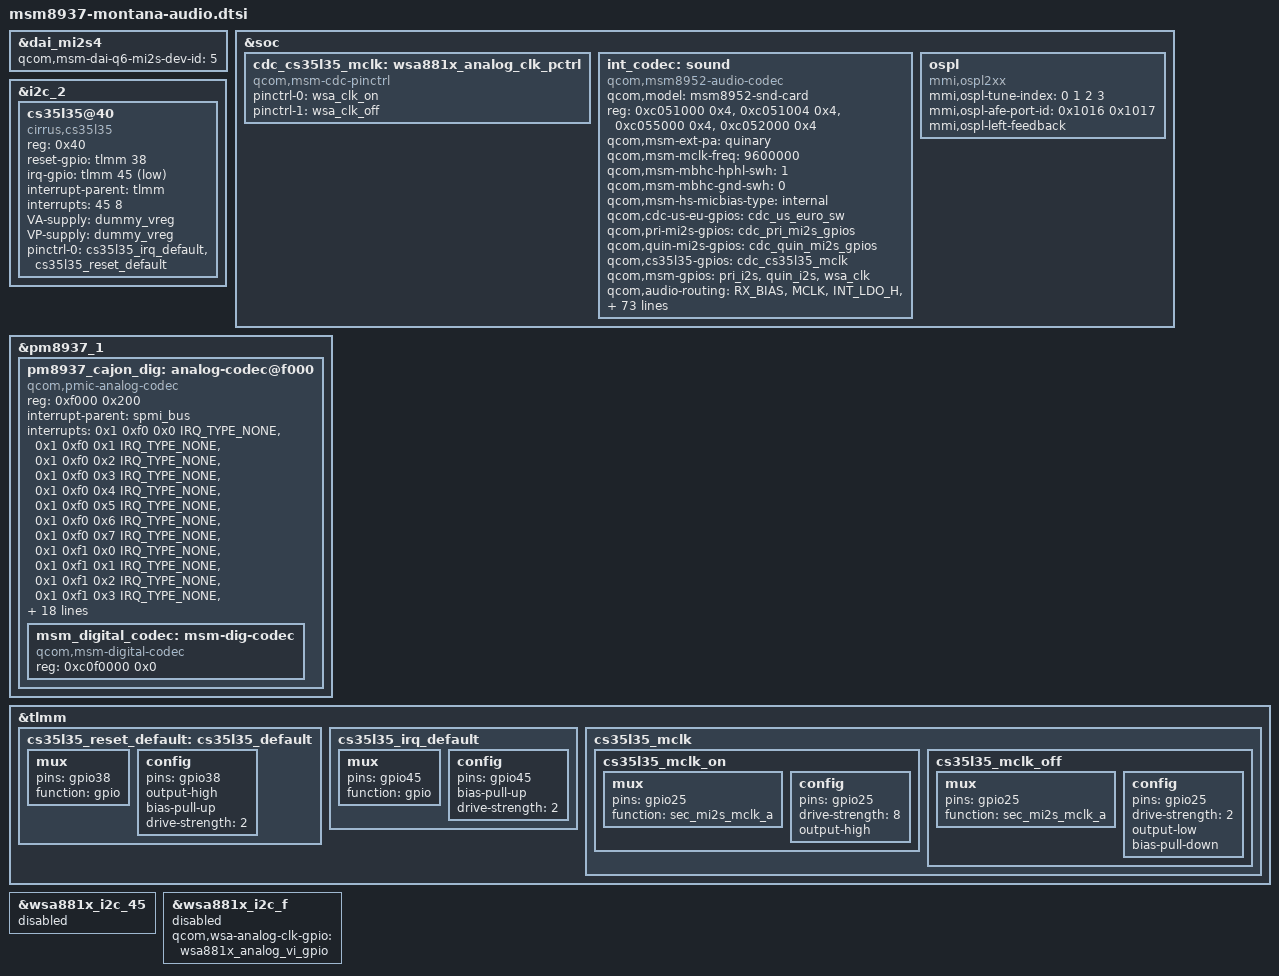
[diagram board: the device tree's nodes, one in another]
/*
 * Copyright (c) 2018, The Linux Foundation. All rights reserved.
 *
 * This program is free software; you can redistribute it and/or modify
 * it under the terms of the GNU General Public License version 2 and
 * only version 2 as published by the Free Software Foundation.
 *
 * This program is distributed in the hope that it will be useful,
 * but WITHOUT ANY WARRANTY; without even the implied warranty of
 * MERCHANTABILITY or FITNESS FOR A PARTICULAR PURPOSE.  See the
 * GNU General Public License for more details.
 */

&dai_mi2s4 {
	qcom,msm-dai-q6-mi2s-dev-id = <5>;
};

&soc {
	/delete-node/ wsa881x_analog_clk_pctrl;

	cdc_cs35l35_mclk: wsa881x_analog_clk_pctrl {
		compatible = "qcom,msm-cdc-pinctrl";
		pinctrl-names = "aud_active", "aud_sleep";
		pinctrl-0 = <&wsa_clk_on>;
		pinctrl-1 = <&wsa_clk_off>;
	};

	int_codec: sound {
		status = "okay";
		compatible = "qcom,msm8952-audio-codec";
		qcom,model = "msm8952-snd-card";

		reg = <0xc051000 0x4>,
			<0xc051004 0x4>,
			<0xc055000 0x4>,
			<0xc052000 0x4>;
		reg-names = "csr_gp_io_mux_mic_ctl",
			"csr_gp_io_mux_spkr_ctl",
			"csr_gp_io_lpaif_pri_pcm_pri_mode_muxsel",
			"csr_gp_io_mux_quin_ctl";

		qcom,msm-ext-pa = "quinary";
		qcom,msm-mclk-freq = <9600000>;
		qcom,msm-mbhc-hphl-swh = <1>;
		qcom,msm-mbhc-gnd-swh = <0>;
		qcom,msm-hs-micbias-type = "internal";

		qcom,cdc-us-eu-gpios = <&cdc_us_euro_sw>;
		qcom,pri-mi2s-gpios = <&cdc_pri_mi2s_gpios>;
		qcom,quin-mi2s-gpios = <&cdc_quin_mi2s_gpios>;
		qcom,cs35l35-gpios = <&cdc_cs35l35_mclk>;

		/delete-property/ qcom,cdc-us-euro-gpios;
		/delete-property/ qcom,msm-micbias1-ext-cap;
		/delete-property/ qcom,msm-micbias2-ext-cap;

		qcom,msm-gpios =
			"pri_i2s",
			"quin_i2s",
			"wsa_clk";

		qcom,audio-routing =
			"RX_BIAS", "MCLK",
			"INT_LDO_H", "MCLK",
			"MIC BIAS External", "Handset Mic",
			"MIC BIAS Internal2", "Headset Mic",
			"MIC BIAS External", "Secondary Mic",
			"AMIC1", "MIC BIAS External",
			"AMIC2", "MIC BIAS Internal2",
			"AMIC3", "MIC BIAS External";

		asoc-platform = <&pcm0>, <&pcm1>, <&pcm2>, <&voip>, <&voice>,
				<&loopback>, <&compress>, <&hostless>,
				<&afe>, <&lsm>, <&routing>, <&pcm_noirq>;
		asoc-platform-names = "msm-pcm-dsp.0", "msm-pcm-dsp.1",
				"msm-pcm-dsp.2", "msm-voip-dsp",
				"msm-pcm-voice", "msm-pcm-loopback",
				"msm-compress-dsp", "msm-pcm-hostless",
				"msm-pcm-afe", "msm-lsm-client",
				"msm-pcm-routing", "msm-pcm-dsp-noirq";
		asoc-cpu = <&dai_pri_auxpcm>,
			<&dai_mi2s0>, <&dai_mi2s1>,
			<&dai_mi2s2>, <&dai_mi2s3>,
			<&dai_mi2s4>, <&dai_mi2s6>,
			<&sb_0_rx>, <&sb_0_tx>, <&sb_1_rx>, <&sb_1_tx>,
			<&sb_3_rx>, <&sb_3_tx>, <&sb_4_rx>, <&sb_4_tx>,
			<&bt_sco_rx>, <&bt_sco_tx>,
			<&int_fm_rx>, <&int_fm_tx>,
			<&afe_pcm_rx>, <&afe_pcm_tx>,
			<&afe_proxy_rx>, <&afe_proxy_tx>,
			<&incall_record_rx>, <&incall_record_tx>,
			<&incall_music_rx>, <&incall_music_2_rx>;

		asoc-cpu-names = "msm-dai-q6-auxpcm.1",
				"msm-dai-q6-mi2s.0", "msm-dai-q6-mi2s.1",
				"msm-dai-q6-mi2s.2", "msm-dai-q6-mi2s.3",
				"msm-dai-q6-mi2s.4", "msm-dai-q6-mi2s.6",
				"msm-dai-q6-dev.16384", "msmdai-q6-dev.16385",
				"msm-dai-q6-dev.16386", "msm-dai-q6-dev.16387",
				"msm-dai-q6-dev.16390", "msm-dai-q6-dev.16391",
				"msm-dai-q6-dev.16392", "msm-dai-q6-dev.16393",
				"msm-dai-q6-dev.12288", "msm-dai-q6-dev.12289",
				"msm-dai-q6-dev.12292", "msm-dai-q6-dev.12293",
				"msm-dai-q6-dev.224", "msm-dai-q6-dev.225",
				"msm-dai-q6-dev.241", "msm-dai-q6-dev.240",
				"msm-dai-q6-dev.32771", "msm-dai-q6-dev.32772",
				"msm-dai-q6-dev.32773", "msm-dai-q6-dev.32770";

		asoc-codec = <&stub_codec>, <&pm8937_cajon_dig>, <&msm_digital_codec>;
		asoc-codec-names = "msm-stub-codec.1", "analog-codec", "msm-dig-codec";

		msm-vdd-wsa-switch-supply = <&pm8937_l5>;
		qcom,msm-vdd-wsa-switch-voltage = <1800000>;
		qcom,msm-vdd-wsa-switch-current = <10000>;

		qcom,pinctrl-names =
			"all_off",
			"pri_i2s_act",
			"quin_act",
			"quin_pri_i2s_act",
			"cs35l35_mclk_act",
			"cs35l35_mclk_pri_i2s_act",
			"cs35l35_mclk_quin_act",
			"cs35l35_mclk_quin_pri_i2s_act";
		pinctrl-names =
			"all_off",
			"pri_i2s_act",
			"quin_act",
			"quin_pri_i2s_act",
			"cs35l35_mclk_act",
			"cs35l35_mclk_pri_i2s_act",
			"cs35l35_mclk_quin_act",
			"cs35l35_mclk_quin_pri_i2s_act";
		pinctrl-0 = <&cdc_pdm_lines_sus &cdc_pdm_lines_2_sus
			&pri_tlmm_lines_sus &pri_tlmm_ws_sus &wsa_clk_off>;
		pinctrl-1 = <&cdc_pdm_lines_act &cdc_pdm_lines_2_act
			&pri_tlmm_lines_sus &pri_tlmm_ws_sus &wsa_clk_off>;
		pinctrl-2 = <&cdc_pdm_lines_sus &cdc_pdm_lines_2_sus
			&pri_tlmm_lines_act &pri_tlmm_ws_act &wsa_clk_off>;
		pinctrl-3 = <&cdc_pdm_lines_act &cdc_pdm_lines_2_act
			&pri_tlmm_lines_act &pri_tlmm_ws_act &wsa_clk_off>;
		pinctrl-4 = <&cdc_pdm_lines_sus &cdc_pdm_lines_2_sus
			&pri_tlmm_lines_sus &pri_tlmm_ws_sus &wsa_clk_on>;
		pinctrl-5 = <&cdc_pdm_lines_act &cdc_pdm_lines_2_act
			&pri_tlmm_lines_sus &pri_tlmm_ws_sus &wsa_clk_on>;
		pinctrl-6 = <&cdc_pdm_lines_sus &cdc_pdm_lines_2_sus
			&pri_tlmm_lines_act &pri_tlmm_ws_act &wsa_clk_on>;
		pinctrl-7 = <&cdc_pdm_lines_act &cdc_pdm_lines_2_act
			&pri_tlmm_lines_act &pri_tlmm_ws_act &wsa_clk_on>;

		/delete-property/ asoc-wsa-codec-names;
		/delete-property/ asoc-wsa-codec-prefixes;
		/delete-property/ qcom,hdmi-dba-codec-rx;
	};

	ospl {
		compatible = "mmi,ospl2xx";
		status = "ok";
		mmi,ospl-tune-index = <0 1 2 3>;
		mmi,ospl-afe-port-id = <0x1016 0x1017>;
		mmi,ospl-left-feedback;
	};
};

&i2c_2 {
	cs35l35@40 {
		compatible = "cirrus,cs35l35";
		reg = <0x40>;
		reset-gpio = <&tlmm 38 0>;
		irq-gpio = <&tlmm 45 1>;
		interrupt-parent = <&tlmm>;
		interrupts = <45 8>;

		VA-supply = <&dummy_vreg>;
		VP-supply = <&dummy_vreg>;
		pinctrl-names = "default";
		pinctrl-0 = <&cs35l35_irq_default &cs35l35_reset_default>;
	};
};

&pm8937_1 {
	pm8937_cajon_dig: analog-codec@f000 {
		compatible = "qcom,pmic-analog-codec";
		reg = <0xf000 0x200>;
		interrupt-parent = <&spmi_bus>;
		interrupts = <0x1 0xf0 0x0 IRQ_TYPE_NONE>,
			     <0x1 0xf0 0x1 IRQ_TYPE_NONE>,
			     <0x1 0xf0 0x2 IRQ_TYPE_NONE>,
			     <0x1 0xf0 0x3 IRQ_TYPE_NONE>,
			     <0x1 0xf0 0x4 IRQ_TYPE_NONE>,
			     <0x1 0xf0 0x5 IRQ_TYPE_NONE>,
			     <0x1 0xf0 0x6 IRQ_TYPE_NONE>,
			     <0x1 0xf0 0x7 IRQ_TYPE_NONE>,
			     <0x1 0xf1 0x0 IRQ_TYPE_NONE>,
			     <0x1 0xf1 0x1 IRQ_TYPE_NONE>,
			     <0x1 0xf1 0x2 IRQ_TYPE_NONE>,
			     <0x1 0xf1 0x3 IRQ_TYPE_NONE>,
			     <0x1 0xf1 0x4 IRQ_TYPE_NONE>,
			     <0x1 0xf1 0x5 IRQ_TYPE_NONE>;
		interrupt-names = "spk_cnp_int",
				  "spk_clip_int",
				  "spk_ocp_int",
				  "ins_rem_det1",
				  "but_rel_det",
				  "but_press_det",
				  "ins_rem_det",
				  "mbhc_int",
				  "ear_ocp_int",
				  "hphr_ocp_int",
				  "hphl_ocp_det",
				  "ear_cnp_int",
				  "hphr_cnp_int",
				  "hphl_cnp_int";

		cdc-vdda-cp-supply = <&pm8937_s4>;
		qcom,cdc-vdda-cp-voltage = <2050000 2050000>;
		qcom,cdc-vdda-cp-current = <210000>;

		cdc-vdd-io-supply = <&pm8937_l5>;
		qcom,cdc-vdd-io-voltage = <1800000 1800000>;
		qcom,cdc-vdd-io-current = <5000>;

		cdc-vdd-pa-supply = <&pm8937_s4>;
		qcom,cdc-vdd-pa-voltage = <2050000 2050000>;
		qcom,cdc-vdd-pa-current = <260000>;

		cdc-vdd-mic-bias-supply = <&pm8937_l13>;
		qcom,cdc-vdd-mic-bias-voltage = <3075000 3075000>;
		qcom,cdc-vdd-mic-bias-current = <5000>;

		qcom,cdc-mclk-clk-rate = <9600000>;

		qcom,cdc-static-supplies = "cdc-vdd-io",
						"cdc-vdd-pa",
						"cdc-vdda-cp";

		qcom,cdc-on-demand-supplies = "cdc-vdd-mic-bias";

		msm_digital_codec: msm-dig-codec {
			compatible = "qcom,msm-digital-codec";
			reg = <0xc0f0000 0x0>;
		};
	};
};

&tlmm {
	cs35l35_reset_default: cs35l35_default{
		mux {
			pins = "gpio38";
			function = "gpio";
		};

		config {
			pins = "gpio38";
			output-high;
			bias-pull-up;
			drive-strength = <2>;
		};
	};

	cs35l35_irq_default: cs35l35_irq_default {
		mux {
			pins = "gpio45";
			function = "gpio";
		};

		config {
			pins = "gpio45";
			bias-pull-up;
			drive-strength = <2>;
		};
	};

	cs35l35_mclk {
		cs35l35_mclk_on: cs35l35_mclk_on {
			mux {
				pins = "gpio25";
				function = "sec_mi2s_mclk_a";
			};

			config {
				pins = "gpio25";
				drive-strength = <8>;
				output-high;
			};
		};

		cs35l35_mclk_off: cs35l35_mclk_off {
			mux {
				pins = "gpio25";
				function = "sec_mi2s_mclk_a";
			};

			config {
				pins = "gpio25";
				drive-strength = <2>;
				output-low;
				bias-pull-down;
			};
		};
	};
};

&wsa881x_i2c_45 {
	status = "disabled";
};

&wsa881x_i2c_f {
	status = "disabled";
	qcom,wsa-analog-clk-gpio = <&wsa881x_analog_vi_gpio>;
};
